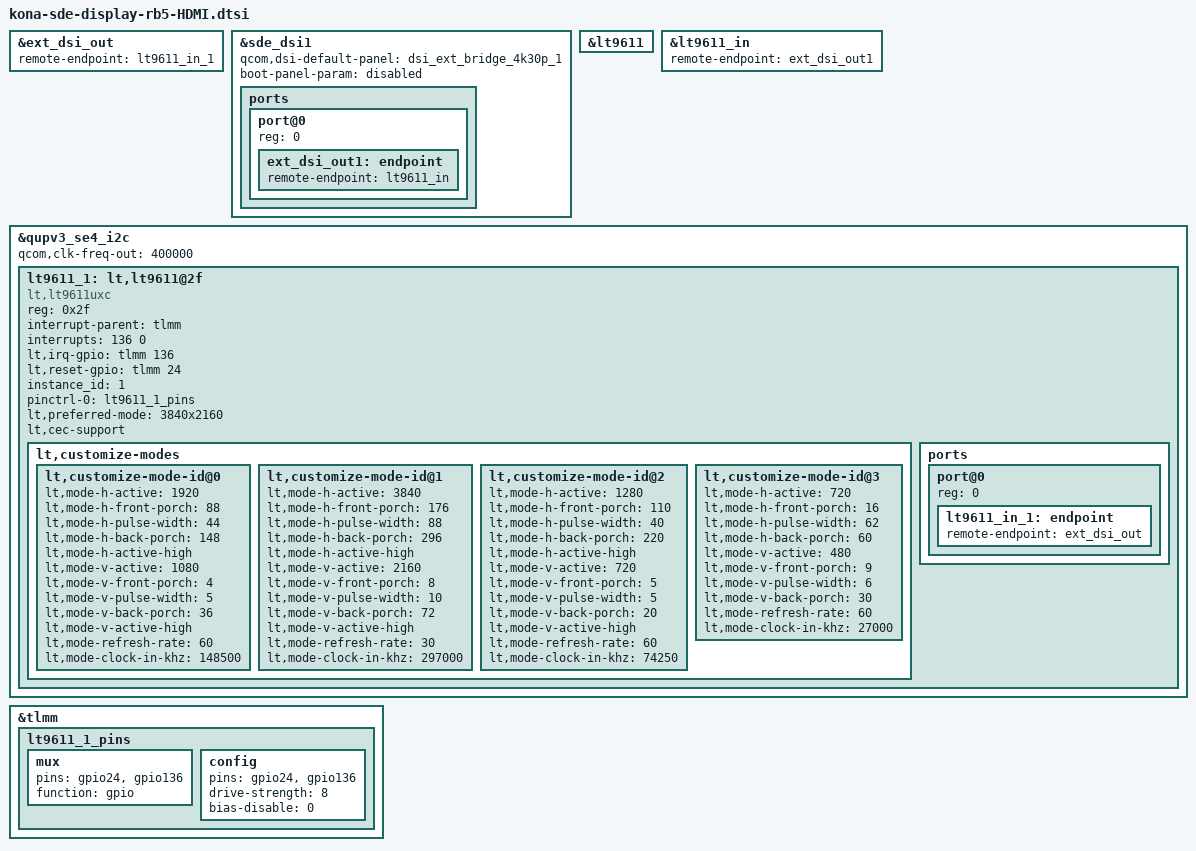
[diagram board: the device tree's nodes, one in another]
#include "kona-sde-display-iot-v2.1-rb5.dtsi"

&ext_dsi_out {
	remote-endpoint = <&lt9611_in_1>;
};

&sde_dsi1 {
	qcom,dsi-default-panel = <&dsi_ext_bridge_4k30p_1>;
	boot-panel-param = "disabled";

	ports {
		#address-cells = <1>;
		#size-cells = <0>;

		port@0 {
			reg = <0>;
			ext_dsi_out1: endpoint {
				remote-endpoint = <&lt9611_in>;
			};
		};
	};
};

&lt9611 {
	status = "okay";
	/delete-property/ lt,audio-support;
	lt,ext-disp = <>;
	/delete-property/ lt,ext-disp;
};

&lt9611_in {
	remote-endpoint = <&ext_dsi_out1>;
};

&qupv3_se4_i2c {
	status = "okay";
	qcom,clk-freq-out = <400000>;
	lt9611_1: lt,lt9611@2f {
		compatible = "lt,lt9611uxc";
		reg = <0x2f>;
		interrupt-parent = <&tlmm>;
		interrupts = <136 0>;
		interrupt-names = "lt_irq";
		lt,irq-gpio = <&tlmm 136 0x0>;
		lt,reset-gpio = <&tlmm 24 0x0>;
		instance_id = <1>;

		pinctrl-names = "default";
		pinctrl-0 = <&lt9611_1_pins>;

		lt,preferred-mode = "3840x2160";
		lt,cec-support;

		lt,customize-modes {
			lt,customize-mode-id@0 {
				lt,mode-h-active = <1920>;
				lt,mode-h-front-porch = <88>;
				lt,mode-h-pulse-width = <44>;
				lt,mode-h-back-porch = <148>;
				lt,mode-h-active-high;
				lt,mode-v-active = <1080>;
				lt,mode-v-front-porch = <4>;
				lt,mode-v-pulse-width = <5>;
				lt,mode-v-back-porch = <36>;
				lt,mode-v-active-high;
				lt,mode-refresh-rate = <60>;
				lt,mode-clock-in-khz = <148500>;
			};

			lt,customize-mode-id@1 {
				lt,mode-h-active = <3840>;
				lt,mode-h-front-porch = <176>;
				lt,mode-h-pulse-width = <88>;
				lt,mode-h-back-porch = <296>;
				lt,mode-h-active-high;
				lt,mode-v-active = <2160>;
				lt,mode-v-front-porch = <8>;
				lt,mode-v-pulse-width = <10>;
				lt,mode-v-back-porch = <72>;
				lt,mode-v-active-high;
				lt,mode-refresh-rate = <30>;
				lt,mode-clock-in-khz = <297000>;
			};

			lt,customize-mode-id@2 {
				lt,mode-h-active = <1280>;
				lt,mode-h-front-porch = <110>;
				lt,mode-h-pulse-width = <40>;
				lt,mode-h-back-porch = <220>;
				lt,mode-h-active-high;
				lt,mode-v-active = <720>;
				lt,mode-v-front-porch = <5>;
				lt,mode-v-pulse-width = <5>;
				lt,mode-v-back-porch = <20>;
				lt,mode-v-active-high;
				lt,mode-refresh-rate = <60>;
				lt,mode-clock-in-khz = <74250>;
			};


			lt,customize-mode-id@3 {
				lt,mode-h-active = <720>;
				lt,mode-h-front-porch = <16>;
				lt,mode-h-pulse-width = <62>;
				lt,mode-h-back-porch = <60>;
				lt,mode-v-active = <480>;
				lt,mode-v-front-porch = <9>;
				lt,mode-v-pulse-width = <6>;
				lt,mode-v-back-porch = <30>;
				lt,mode-refresh-rate = <60>;
				lt,mode-clock-in-khz = <27000>;
			};
		};

		ports {
			#address-cells = <1>;
			#size-cells = <0>;

			port@0 {
				reg = <0>;
				lt9611_in_1: endpoint {
					remote-endpoint = <&ext_dsi_out>;
				};
			};
		};
	};
};

&tlmm {
	lt9611_1_pins: lt9611_1_pins {
		mux {
			pins = "gpio24", "gpio136";
			function = "gpio";
		};

		config {
			pins = "gpio24", "gpio136";
			drive-strength = <8>;
			bias-disable = <0>;
		};
	};
};

